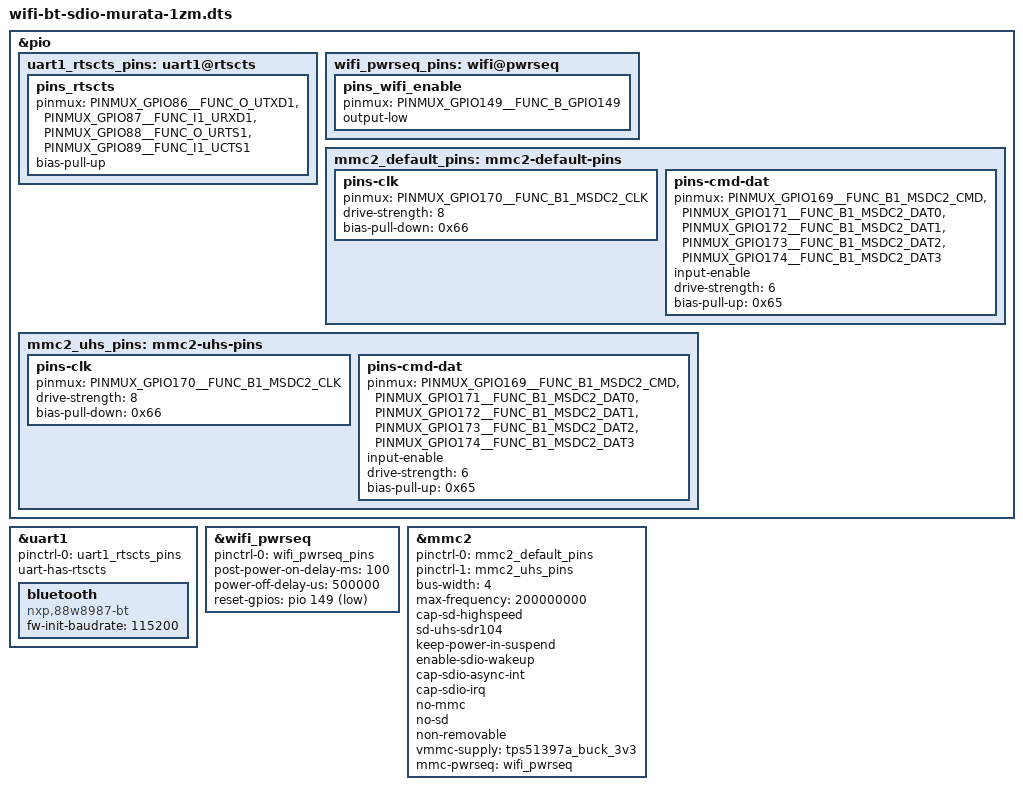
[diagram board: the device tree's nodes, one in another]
// SPDX-License-Identifier: (GPL-2.0 OR MIT)
/*
 * Copyright (C) 2026 Grinn sp. z o.o.
 */

/dts-v1/;
/plugin/;

#include <dt-bindings/pinctrl/mediatek,mt8188-pinfunc.h>
#include <dt-bindings/gpio/gpio.h>

/ {
	fragment@0 {
		target = <&pio>;

		__overlay__ {
			uart1_rtscts_pins: uart1@rtscts {
				pins_rtscts {
					pinmux = <PINMUX_GPIO86__FUNC_O_UTXD1>,
						 <PINMUX_GPIO87__FUNC_I1_URXD1>,
						 <PINMUX_GPIO88__FUNC_O_URTS1>,
						 <PINMUX_GPIO89__FUNC_I1_UCTS1>;
					bias-pull-up;
				};
			};

			wifi_pwrseq_pins: wifi@pwrseq {
				pins_wifi_enable {
					pinmux = <PINMUX_GPIO149__FUNC_B_GPIO149>;
					output-low;
				};
			};

			mmc2_default_pins: mmc2-default-pins {
				pins-clk {
					pinmux = <PINMUX_GPIO170__FUNC_B1_MSDC2_CLK>;
					drive-strength = <8>;
					bias-pull-down = <0x66>;
				};

				pins-cmd-dat {
					pinmux = <PINMUX_GPIO169__FUNC_B1_MSDC2_CMD>,
						 <PINMUX_GPIO171__FUNC_B1_MSDC2_DAT0>,
						 <PINMUX_GPIO172__FUNC_B1_MSDC2_DAT1>,
						 <PINMUX_GPIO173__FUNC_B1_MSDC2_DAT2>,
						 <PINMUX_GPIO174__FUNC_B1_MSDC2_DAT3>;
					input-enable;
					drive-strength = <6>;
					bias-pull-up = <0x65>;
				};
			};

			mmc2_uhs_pins: mmc2-uhs-pins {
				pins-clk {
					pinmux = <PINMUX_GPIO170__FUNC_B1_MSDC2_CLK>;
					drive-strength = <8>;
					bias-pull-down = <0x66>;
				};

				pins-cmd-dat {
					pinmux = <PINMUX_GPIO169__FUNC_B1_MSDC2_CMD>,
						 <PINMUX_GPIO171__FUNC_B1_MSDC2_DAT0>,
						 <PINMUX_GPIO172__FUNC_B1_MSDC2_DAT1>,
						 <PINMUX_GPIO173__FUNC_B1_MSDC2_DAT2>,
						 <PINMUX_GPIO174__FUNC_B1_MSDC2_DAT3>;
					input-enable;
					drive-strength = <6>;
					bias-pull-up = <0x65>;
				};
			};
		};
	};

	fragment@1 {
		target = <&uart1>;

		__overlay__ {
			pinctrl-0 = <&uart1_rtscts_pins>;
			pinctrl-names = "default";
			uart-has-rtscts;

			bluetooth {
				compatible = "nxp,88w8987-bt";
				fw-init-baudrate = <115200>;
			};
		};
	};

	fragment@2 {
		target = <&wifi_pwrseq>;

		__overlay__ {
			pinctrl-names = "default";
			pinctrl-0 = <&wifi_pwrseq_pins>;
			status = "okay";
			post-power-on-delay-ms = <100>;
			power-off-delay-us = <500000>;
			reset-gpios = <&pio 149 GPIO_ACTIVE_LOW>;
		};
	};

	fragment@3 {
		target = <&mmc2>;

		__overlay__ {
			status = "okay";
			pinctrl-names = "default", "state_uhs";
			pinctrl-0 = <&mmc2_default_pins>;
			pinctrl-1 = <&mmc2_uhs_pins>;
			bus-width = <4>;
			max-frequency = <200000000>;
			cap-sd-highspeed;
			sd-uhs-sdr104;
			keep-power-in-suspend;
			enable-sdio-wakeup;
			cap-sdio-async-int;
			cap-sdio-irq;
			no-mmc;
			no-sd;
			non-removable;
			vmmc-supply = <&tps51397a_buck_3v3>;
			mmc-pwrseq = <&wifi_pwrseq>;
		};
	};
};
